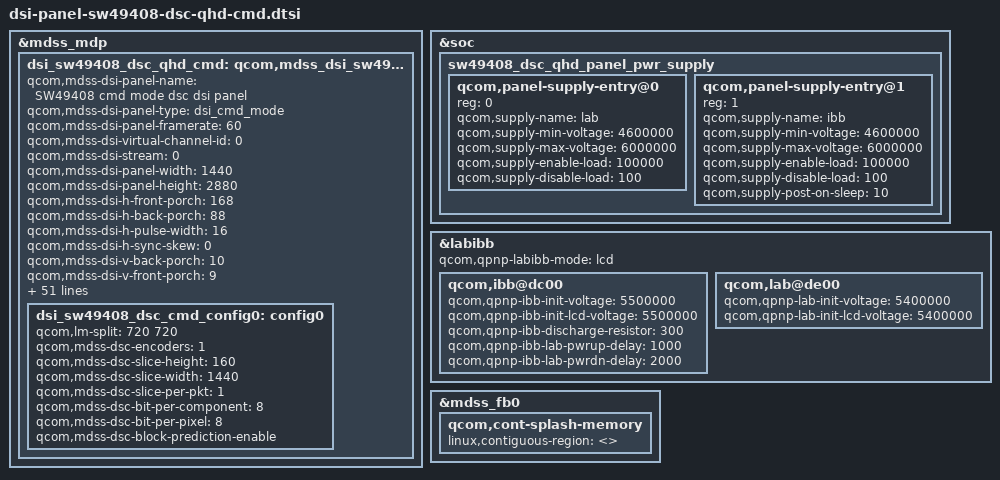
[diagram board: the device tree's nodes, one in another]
/* Copyright (c) 2017, LGE Inc. All rights reserved.
 *
 * This program is free software; you can redistribute it and/or modify
 * it under the terms of the GNU General Public License version 2 and
 * only version 2 as published by the Free Software Foundation.
 *
 * This program is distributed in the hope that it will be useful,
 * but WITHOUT ANY WARRANTY; without even the implied warranty of
 * MERCHANTABILITY or FITNESS FOR A PARTICULAR PURPOSE.  See the
 * GNU General Public License for more details.
 */

&mdss_mdp {
    dsi_sw49408_dsc_qhd_cmd: qcom,mdss_dsi_sw49408_dsc_qhd_cmd {
		qcom,mdss-dsi-panel-name = "SW49408 cmd mode dsc dsi panel";

		qcom,mdss-dsi-panel-type = "dsi_cmd_mode";
		qcom,mdss-dsi-panel-framerate = <60>;
		qcom,mdss-dsi-virtual-channel-id = <0>;
		qcom,mdss-dsi-stream = <0>;
		qcom,mdss-dsi-panel-width = <1440>;
		qcom,mdss-dsi-panel-height = <2880>;
		qcom,mdss-dsi-h-front-porch = <168>;
		qcom,mdss-dsi-h-back-porch = <88>;
		qcom,mdss-dsi-h-pulse-width = <16>;
		qcom,mdss-dsi-h-sync-skew = <0>;
		qcom,mdss-dsi-v-back-porch = <10>;
		qcom,mdss-dsi-v-front-porch = <9>; /* Elsa : 100 */
		qcom,mdss-dsi-v-pulse-width = <1>;
		qcom,mdss-dsi-h-left-border = <0>;
		qcom,mdss-dsi-h-right-border = <0>;
		qcom,mdss-dsi-v-top-border = <0>;
		qcom,mdss-dsi-v-bottom-border = <0>;
		qcom,mdss-dsi-bpp = <24>;
		qcom,mdss-dsi-color-order = "rgb_swap_rgb";
		qcom,mdss-dsi-underflow-color = <0xff>;
		qcom,mdss-dsi-border-color = <0>;
		qcom,mdss-dsi-h-sync-pulse = <0>;
		qcom,mdss-dsi-traffic-mode = "burst_mode";
		qcom,mdss-dsi-lane-map = "lane_map_0123";
		qcom,mdss-dsi-bllp-eof-power-mode;
		qcom,mdss-dsi-bllp-power-mode;
		qcom,partial-update-enabled;
		qcom,panel-roi-alignment = <1440 160 1440 160 1440 160>;
		qcom,mdss-dsi-lane-0-state;
		qcom,mdss-dsi-lane-1-state;
		qcom,mdss-dsi-lane-2-state;
		qcom,mdss-dsi-lane-3-state;
		qcom,mdss-dsi-hor-line-idle = <0 40 256>,
						<40 120 128>,
						<120 240 64>;
		qcom,mdss-dsi-reset-sequence = <1 10>, <0 10>, <1 10>;
		qcom,mdss-dsi-dma-trigger = "trigger_sw";
		qcom,mdss-dsi-mdp-trigger = "none";
		qcom,mdss-dsi-te-pin-select = <1>;
		qcom,mdss-dsi-wr-mem-start = <0x2c>;
		qcom,mdss-dsi-wr-mem-continue = <0x3c>;
		qcom,mdss-dsi-te-dcs-command = <1>;
		qcom,mdss-dsi-te-check-enable;
		qcom,mdss-dsi-te-using-te-pin;
		qcom,ulps-enabled;
		qcom,suspend-ulps-enabled;
		qcom,mdss-dsi-lp11-init;
		qcom,mdss-dsi-tx-eot-append;
		qcom,mdss-mdp-transfer-time-us = <15000>;

		qcom,mdss-dsi-on-command = [
			/* Manufacturer Command Protection */
			15 01 00 00 00 00 02 B0 AC
			/*Left Side GIP pad setting*/
			39 01 00 00 00 00 0E E5 1A 0D 0C 0E 1A 1A 01 05 07 09 0B 1A 11
			/*Right Side GIP pad setting*/
			39 01 00 00 00 00 0E E6 1A 0D 0C 0E 1A 1A 00 04 06 08 0A 1A 11
			/*Left Side Mux Pad Setting*/
			39 01 00 00 00 00 07 E7 18 17 16 15 14 13
			/*Right Side Mux Pad Setting*/
			39 01 00 00 00 00 07 E8 18 17 16 15 14 13
			/* Page Address Set */
			39 01 00 00 00 00 05 2B 00 00 0B 3F
			/* Partial Area Set */
			39 01 00 00 00 00 05 30 00 00 03 1F
			/* Tearing Effect Line on */
			15 01 00 00 00 00 02 35 00
			/* Write Display Brightness */
			15 01 00 00 00 00 02 51 FF
			/* Write Control Display */
			15 01 00 00 00 00 02 53 2C
			/* Display Control 1 */
			39 01 00 00 00 00 08 B3 08 07 28 C8 1A 94 02
			/* Display Control 2 */
			39 01 00 00 00 00 0E B4 91 08 00 0C 0C 0C 0C 0A 0A 0A 0A 0A 0A
			/* Display Control 3 */
			39 01 00 00 00 00 0F B5 28 14 2A C8 36 08 00 0A 00 C0 93 13 31 31
			/* Display Control 4 */
			39 01 00 00 00 00 09 B6 26 0F 10 C0 00 2C C2 00
			/* Panel Setting */
			39 01 00 00 00 00 05 B7 61 F5 EC B3
			/* Touch Timing Control */
			39 01 00 00 00 00 20 B8 17 02 90 40 CA A0 0C 00 00 18 33 04 01 90 01 45 16 C2 21 00 00 10 01 15
			01 0A 00 50 0A 40 9C
			/* Touch Source Setting */
			39 01 00 00 00 00 06 B9 64 64 2A 3F EE
			/* Internal Oscillator Setting */
			39 01 00 00 00 00 04 C0 9C 08 10
			/* Power Control 1 */
			39 01 00 00 00 00 07 C1 01 00 F0 C2 CF 0C
			/* Power Control 2 */
			39 01 00 00 00 00 05 C2 CC 44 44 00
			/* Power Control 3 */
			39 01 00 00 00 00 09 C3 35 44 22 26 21 00 15 DD
			/* Power Control 4 */
			39 01 00 00 00 00 05 C4 0A 02 9E A4
			/* Power Control 5 */
			39 01 00 00 00 00 07 C5 A2 38 28 14 D4 0F
			/* Power Sequence Option Configuration */
			39 01 00 00 00 00 06 C9 05 5D 03 04 01
			/* APO Control */
			39 01 00 00 00 00 03 CA 9F 10
			/* LFD Control */
			39 01 00 00 00 00 06 CB 73 90 3D 3D 8C
			/* Tail TFT Setting */
			39 01 00 00 00 00 06 CC 14 50 50 90 41
			/* U2 Control */
			39 01 00 00 00 00 04 CD 67 86 C0
			/* Positive Gamma Curve for Red */
			39 01 00 00 00 00 0E D0 00 12 20 2E 3A 41 4D 43 36 27 15 00 03
			/* Negative Gamma Curve for Red */
			39 01 00 00 00 00 0E D1 00 12 20 2E 3A 41 4D 43 36 27 15 00 03
			/* Positive Gamma Curve for Green */
			39 01 00 00 00 00 0E D2 00 12 20 2E 3A 41 4D 43 36 27 15 00 03
			/* Negative Gamma Curve for Green */
			39 01 00 00 00 00 0E D3 00 12 20 2E 3A 41 4D 43 36 27 15 00 03
			/* Positive Gamma Curve for Blue */
			39 01 00 00 00 00 0E D4 00 12 20 2E 3A 41 4D 43 36 27 15 00 03
			/* Negative Gamma Curve for Blue */
			39 01 00 00 00 00 0E D5 00 12 20 2E 3A 41 4D 43 36 27 15 00 03
			/* Test1 */
			39 01 00 00 00 00 07 ED 41 68 00 90 00 00
			/* Write Content Adaptive Brightness Control */
			15 01 00 00 00 00 02 55 81
			/* IE Setting1 */
			15 01 00 00 00 00 02 F0 82
			/* IE Setting2 */
			39 01 00 00 00 00 05 F2 01 00 24 00
			/* IE Setting3 */
			39 01 00 00 00 00 0D F3 00 43 83 C0 00 01 00 00 00 00 00 00
			/* CABC Control 1 */
			39 01 00 00 00 00 18 FA 20 40 60 80 A0 C0 E0 10 1C 20 20 1F 16 18 00 B4 C0 CD DA E8 F0 F7 FF
			/* CABC Control 2*/
			39 01 00 00 00 00 0E FB B1 80 D0 06 40 7B 02 FF 12 22 22 12 22
			/* Normal Display mode on */
			05 01 00 00 00 00 01 13
			/* Display On */
			05 01 00 00 00 00 01 29
			/* Sleep Out + min 90ms */
			05 01 00 00 5A 00 01 11
			];

		qcom,mdss-dsi-on-command-state = "dsi_lp_mode";
		qcom,mdss-dsi-off-command = [
			/* Display Off */
			05 01 00 00 00 00 01 28
			/* Sleep In + min 90ms */
			05 01 00 00 5A 00 01 10
		];
		qcom,mdss-dsi-off-command-state = "dsi_hs_mode";

		qcom,mode-control-dsi-state = "dsi_lp_mode";
		qcom,mdss-pan-physical-width-dimension = <65>;
		qcom,mdss-pan-physical-height-dimension = <130>;

		qcom,compression-mode = "dsc";
		qcom,config-select = <&dsi_sw49408_dsc_cmd_config0>;

		qcom,mdss-dsc-version = <0x11>;
		qcom,mdss-dsc-scr-version = <0x1>;

		dsi_sw49408_dsc_cmd_config0: config0 {
		        qcom,lm-split = <720 720>;
		        qcom,mdss-dsc-encoders = <1>; /* 3D Mux */
		        qcom,mdss-dsc-slice-height = <160>;
		        qcom,mdss-dsc-slice-width = <1440>;
		        qcom,mdss-dsc-slice-per-pkt = <1>;

		        qcom,mdss-dsc-bit-per-component = <8>;
		        qcom,mdss-dsc-bit-per-pixel = <8>;
		        qcom,mdss-dsc-block-prediction-enable;
		};
	};
};

&soc {
	sw49408_dsc_qhd_panel_pwr_supply: sw49408_dsc_qhd_panel_pwr_supply {
		#address-cells = <1>;
		#size-cells = <0>;

		qcom,panel-supply-entry@0 {
			reg = <0>;
			qcom,supply-name = "lab";
			qcom,supply-min-voltage = <4600000>;
			qcom,supply-max-voltage = <6000000>;
			qcom,supply-enable-load = <100000>;
			qcom,supply-disable-load = <100>;
		};

		qcom,panel-supply-entry@1 {
			reg = <1>;
			qcom,supply-name = "ibb";
			qcom,supply-min-voltage = <4600000>;
			qcom,supply-max-voltage = <6000000>;
			qcom,supply-enable-load = <100000>;
			qcom,supply-disable-load = <100>;
			qcom,supply-post-on-sleep = <10>;
		};
	};
};

/* Start to override parameters in msm-pmi8998.dtsi */
&labibb {
	status = "okay";
	qcom,qpnp-labibb-mode = "lcd";

	qcom,ibb@dc00 {
		qcom,qpnp-ibb-init-voltage = <5500000>;
		qcom,qpnp-ibb-init-lcd-voltage = <5500000>;
		qcom,qpnp-ibb-discharge-resistor = <300>;
		qcom,qpnp-ibb-lab-pwrup-delay = <1000>;
		qcom,qpnp-ibb-lab-pwrdn-delay = <2000>;
	};
	qcom,lab@de00 {
		qcom,qpnp-lab-init-voltage = <5400000>;
		qcom,qpnp-lab-init-lcd-voltage = <5400000>;
	};
};

&mdss_fb0 {
	qcom,cont-splash-memory {
		linux,contiguous-region = <>;
	};
};

/* End of overriding parameters in msm-pmi8998.dtsi */

